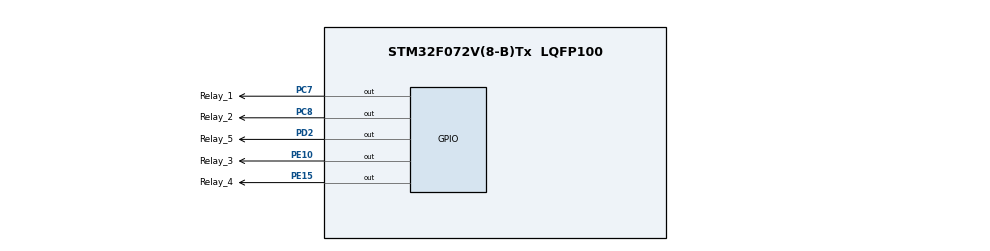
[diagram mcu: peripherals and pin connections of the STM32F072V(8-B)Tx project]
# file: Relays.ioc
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Mcu.Family=STM32F0
Mcu.Name=STM32F072V(8-B)Tx
Mcu.Package=LQFP100
PC7.GPIO_Label=Relay_1
PC7.Signal=GPIO_Output
PC8.GPIO_Label=Relay_2
PC8.Signal=GPIO_Output
PD2.GPIO_Label=Relay_5
PD2.Signal=GPIO_Output
PE10.GPIO_Label=Relay_3
PE10.Signal=GPIO_Output
PE15.GPIO_Label=Relay_4
PE15.Signal=GPIO_Output
ProjectManager.HeapSize=0x200
ProjectManager.StackSize=0x400
ProjectManager.TargetToolchain=STM32CubeIDE
board=custom

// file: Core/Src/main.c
/* USER CODE BEGIN Header */
/**
  ******************************************************************************
  * @file           : main.c
  * @brief          : Main program body
  ******************************************************************************
  * @attention
  *
  * Copyright (c) 2023 STMicroelectronics.
  * All rights reserved.
  *
  * This software is licensed under terms that can be found in the LICENSE file
  * in the root directory of this software component.
  * If no LICENSE file comes with this software, it is provided AS-IS.
  *
  ******************************************************************************
  */
/* USER CODE END Header */
#include "main.h"

void SystemClock_Config(void);
static void MX_GPIO_Init(void);

int main(void)
{

  /* MCU Configuration--------------------------------------------------------*/

  /* Reset of all peripherals, Initializes the Flash interface and the Systick. */
  HAL_Init();

  /* Configure the system clock */
  SystemClock_Config();

  /* Initialize all configured peripherals */
  MX_GPIO_Init();

  /* Infinite loop */
  /* USER CODE BEGIN WHILE */
  uint32_t arr[5] = {Relay_1_GPIO_Port,Relay_2_GPIO_Port,Relay_3_GPIO_Port,Relay_4_GPIO_Port,Relay_5_GPIO_Port};
  uint16_t arr_1[5] = {Relay_1_Pin,Relay_2_Pin,Relay_3_Pin,Relay_4_Pin,Relay_5_Pin};
  while (1)
  {

	  int j=0;

	  for(int i=0;i<5;i++)
	  {   HAL_GPIO_WritePin(arr[i], arr_1[j], GPIO_PIN_SET);
	      HAL_Delay(1000);
	      HAL_GPIO_WritePin(arr[i], arr_1[j], GPIO_PIN_RESET);
		  j++;
	  }

    /* USER CODE END WHILE */

  }
}

void SystemClock_Config(void)
{
  RCC_OscInitTypeDef RCC_OscInitStruct = {0};
  RCC_ClkInitTypeDef RCC_ClkInitStruct = {0};

  /** Initializes the RCC Oscillators according to the specified parameters
  * in the RCC_OscInitTypeDef structure.
  */
  RCC_OscInitStruct.OscillatorType = RCC_OSCILLATORTYPE_HSI;
  RCC_OscInitStruct.HSIState = RCC_HSI_ON;
  RCC_OscInitStruct.HSICalibrationValue = RCC_HSICALIBRATION_DEFAULT;
  RCC_OscInitStruct.PLL.PLLState = RCC_PLL_NONE;
  if (HAL_RCC_OscConfig(&RCC_OscInitStruct) != HAL_OK)
  {
    Error_Handler();
  }

  /** Initializes the CPU, AHB and APB buses clocks
  */
  RCC_ClkInitStruct.ClockType = RCC_CLOCKTYPE_HCLK|RCC_CLOCKTYPE_SYSCLK
                              |RCC_CLOCKTYPE_PCLK1;
  RCC_ClkInitStruct.SYSCLKSource = RCC_SYSCLKSOURCE_HSI;
  RCC_ClkInitStruct.AHBCLKDivider = RCC_SYSCLK_DIV1;
  RCC_ClkInitStruct.APB1CLKDivider = RCC_HCLK_DIV1;

  if (HAL_RCC_ClockConfig(&RCC_ClkInitStruct, FLASH_LATENCY_0) != HAL_OK)
  {
    Error_Handler();
  }
}

static void MX_GPIO_Init(void)
{
  GPIO_InitTypeDef GPIO_InitStruct = {0};

  /* GPIO Ports Clock Enable */
  __HAL_RCC_GPIOE_CLK_ENABLE();
  __HAL_RCC_GPIOC_CLK_ENABLE();
  __HAL_RCC_GPIOD_CLK_ENABLE();

  /*Configure GPIO pin Output Level */
  HAL_GPIO_WritePin(GPIOE, Relay_3_Pin|Relay_4_Pin, GPIO_PIN_RESET);

  /*Configure GPIO pin Output Level */
  HAL_GPIO_WritePin(GPIOC, Relay_1_Pin|Relay_2_Pin, GPIO_PIN_RESET);

  /*Configure GPIO pin Output Level */
  HAL_GPIO_WritePin(Relay_5_GPIO_Port, Relay_5_Pin, GPIO_PIN_RESET);

  /*Configure GPIO pins : Relay_3_Pin Relay_4_Pin */
  GPIO_InitStruct.Pin = Relay_3_Pin|Relay_4_Pin;
  GPIO_InitStruct.Mode = GPIO_MODE_OUTPUT_PP;
  GPIO_InitStruct.Pull = GPIO_NOPULL;
  GPIO_InitStruct.Speed = GPIO_SPEED_FREQ_LOW;
  HAL_GPIO_Init(GPIOE, &GPIO_InitStruct);

  /*Configure GPIO pins : Relay_1_Pin Relay_2_Pin */
  GPIO_InitStruct.Pin = Relay_1_Pin|Relay_2_Pin;
  GPIO_InitStruct.Mode = GPIO_MODE_OUTPUT_PP;
  GPIO_InitStruct.Pull = GPIO_NOPULL;
  GPIO_InitStruct.Speed = GPIO_SPEED_FREQ_LOW;
  HAL_GPIO_Init(GPIOC, &GPIO_InitStruct);

  /*Configure GPIO pin : Relay_5_Pin */
  GPIO_InitStruct.Pin = Relay_5_Pin;
  GPIO_InitStruct.Mode = GPIO_MODE_OUTPUT_PP;
  GPIO_InitStruct.Pull = GPIO_NOPULL;
  GPIO_InitStruct.Speed = GPIO_SPEED_FREQ_LOW;
  HAL_GPIO_Init(Relay_5_GPIO_Port, &GPIO_InitStruct);

}

void Error_Handler(void)
{
  __disable_irq();
  while (1)
  {
  }
}
